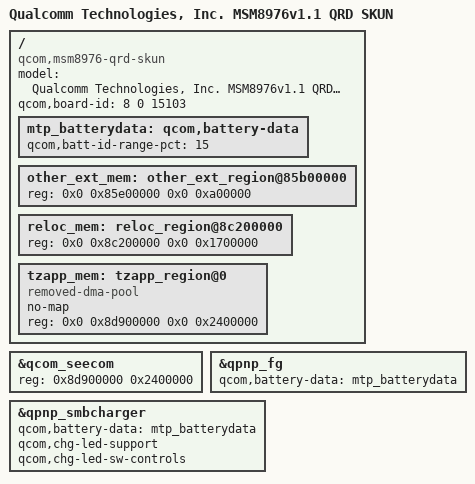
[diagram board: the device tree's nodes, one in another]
/*
 * Copyright (c) 2015, The Linux Foundation. All rights reserved.
 *
 * This program is free software; you can redistribute it and/or modify
 * it under the terms of the GNU General Public License version 2 and
 * only version 2 as published by the Free Software Foundation.
 *
 * This program is distributed in the hope that it will be useful,
 * but WITHOUT ANY WARRANTY; without even the implied warranty of
 * MERCHANTABILITY or FITNESS FOR A PARTICULAR PURPOSE.  See the
 * GNU General Public License for more details.
 */

/dts-v1/;
#include "msm8976-v1.1.dtsi"
#include "oppo-msm8976/msm8976-mtp.dtsi"
#include "oppo-msm8976/15103/msm8976-mtp.dtsi"

/ {
	/*
	 * Device was shipped with a bootloader recognizing MTP board ID,
	 * but shares much in common with QRD SKUN, so we report as QRD SKUN
	 * while keeping MTP bindings for simplicity.
	 */
	model = "Qualcomm Technologies, Inc. MSM8976v1.1 QRD SKUN";
	compatible = "qcom,msm8976-qrd-skun", "qcom,msm8976-qrd",
		   "qcom,msm8976", "qcom,qrd";
	qcom,board-id= <8 0 15103>; // NOTE: Lollipop bootloader used OPPO_PROJECT hax in QCDT.

	mtp_batterydata: qcom,battery-data {
		qcom,batt-id-range-pct = <15>;
		#include "batterydata-itech-3000mah-4200mv.dtsi"
		#include "batterydata-itech-3000mah.dtsi"
	};

	/*
	 * Reserved memory region changes
	 */
	other_ext_mem: other_ext_region@85b00000 {
		reg = <0x0 0x85e00000 0x0 0xa00000>;
	};

	reloc_mem: reloc_region@8c200000 {
		reg = <0x0 0x8c200000 0x0 0x1700000>;
	};

	tzapp_mem: tzapp_region@0 {
		compatible = "removed-dma-pool";
		no-map;
		reg = <0x0 0x8d900000 0x0 0x2400000>;
	};
};

/* For loading QSEE KM apps */
&qcom_seecom {
	reg = <0x8d900000 0x2400000>;
	/delete-property/ qcom,appsbl-qseecom-support;
};

&qpnp_fg {
	qcom,battery-data = <&mtp_batterydata>;
};

&qpnp_smbcharger {
	qcom,battery-data = <&mtp_batterydata>;
	qcom,chg-led-support;
	qcom,chg-led-sw-controls;
};
